# Polarfire SoC register map
Vendor: Microchip; File version: 1.0
CPU: Microchip PolarFire SoC 1.0, little endian
Registers are 32-bit, read-write, reset 0x0 unless marked. A register's access mark holds for its fields unless they carry their own. Offsets are from the block's base; [hi:lo] are bit positions.

## GEM_A_LO (part 6 of 8) — GEM_A_LO Controller
Base 0x20110000
Same registers: GEM_B_LO 0x20112000, GEM_A_HI 0x28110000, GEM_B_HI 0x28112000
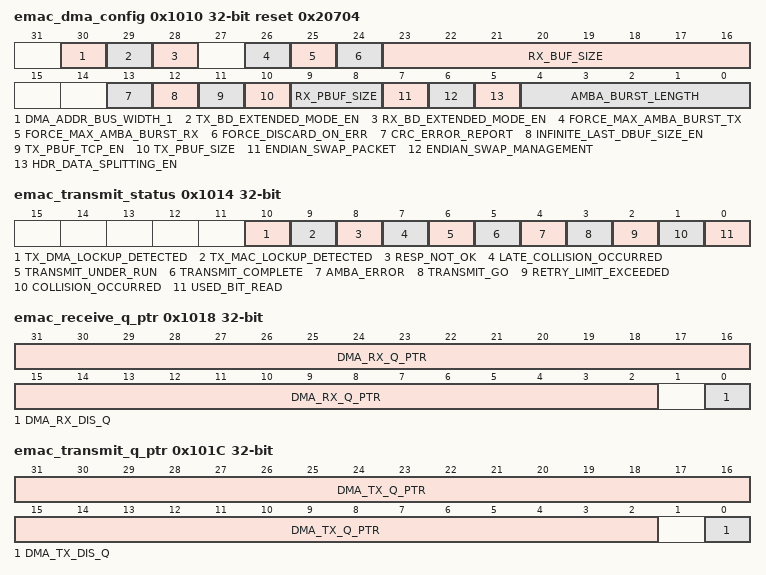
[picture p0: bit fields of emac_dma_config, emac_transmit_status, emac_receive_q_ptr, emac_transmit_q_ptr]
0x1010 emac_dma_config reset 0x20704 — DMA Configuration Register
  [30] DMA_ADDR_BUS_WIDTH_1 — DMA address bus width. 0 = 32b, 1 = 64b.
  [29] TX_BD_EXTENDED_MODE_EN — Enable TX extended BD mode. See TX BD control register definition for description of feature.
  [28] RX_BD_EXTENDED_MODE_EN — Enable RX extended BD mode. See RX BD control register definition for description of feature.
  [26] FORCE_MAX_AMBA_BURST_TX — Force max length bursts on TX. Force the TX DMA to always issue max length bursts on EOP (end of packet) or EOB (end of buffer) transfers as defined by bits 4:0 of this register, even when there is less than max burst data bytes to read. Residual data read is ignored. AHB only - does not apply on AXI bursts (prior to release 1p10) or bursts that break 1k boundary rule - supported on AXI from release 1p10.
  [25] FORCE_MAX_AMBA_BURST_RX — Force max length bursts on RX. Force the RX DMA to always issue max length bursts on EOP (end of packet) or EOB (end of buffer) transfers, even if there is less than max burst real packet data required to write. Any extra bytes of pad data is set to 0x00. AHB only - does not apply on AXI bursts (prior to release 1p10) or bursts that break 1k boundary rule - supported on AXI from release 1p10.
  [24] FORCE_DISCARD_ON_ERR — Auto Discard RX frames during lack of resource. When set, the GEM DMA will automatically discard the next frame (that is the oldest frame) from the receiver packet buffer memory when a receive buffer descriptor is read with its used bit set. When low, then received frames will remain to be stored in the SRAM based packet buffer until AMBA (AHB/AXI) buffer resource next becomes available. In this case if the SRAM memory fills up then there will be a receive overflow condition and the most recently received frame (that is the newest) will be discarded. A write to this bit is ignored if the DMA is not configured in the packet buffer full store and forward mode.
  [23:16] RX_BUF_SIZE — DMA receive buffer size in external AMBA (AHB/AXI) system memory. The value defined by these bits determines the size of buffer to use in main system memory when writing received data. The value is defined in multiples of 64 bytes., :0x01 corresponds to buffers of 64 bytes, :0x02 corresponds to 128 bytes etc., :For example:, :0x02: 128 byte., :0x18: 1536 byte (1*max length frame/buffer), :0xA0: 10240 byte (1*10K jumbo frame/buffer), :0xFF: 16320 byte , :Note that this value should never be written as zero., :Note. The reset value of this field is equal to the gem_rx_buffer_length_def define, which is user configurable.
  [13] CRC_ERROR_REPORT — When the bit is set, bit 16 of the receive buffer descriptor will represent FCS/CRC error (only if frames with FCS are copied to memory as enabled by bit 26 in the network config register). When this bit is clear, bit 16 of the receive buffer descriptor will represent the Canonical format indicator (CFI) bit as extracted from the receive frame (if the receive buffer descriptor is pointing to the last data buffer of the receive frame and the received frame was VLAN tagged).
  [12] INFINITE_LAST_DBUF_SIZE_EN — Forces the receive DMA to consider the data buffer pointed to by last descriptor in the descriptor list to be of elastic size (the last descriptor is the one with its wrap bit set). This means the first buffer pointed to in the list will always contain the beginning of a frame (this helps if there is a desire to build custom logic that interfaces with the receive buffer directly without software intervention). When set the rx_buf_size bits 23:16 in the dma configuration register are ignored for the last receive buffer in the descriptor list and data will be written into the buffer sequentially until the frame is completely received and the buffer descriptor status will be updated with the frame length as normal.
  [11] TX_PBUF_TCP_EN — Transmitter IP, TCP and UDP checksum generation offload enable (not supported when in TX Partial Store and Forward mode). When set, the transmitter checksum generation engine is enabled, to calculate and substitute checksums for transmit frames. When clear, frame data is unaffected. If the GEM is not configured to use the DMA packet buffer, this bit is not implemented and will be treated as reserved, read as 0, ignored on write.
  [10] TX_PBUF_SIZE — Transmitter packet buffer memory size select. Having this bit at zero halves the amount of memory used for the transmit packet buffer. This reduces the amount of memory used by the GEM. It is important to set this bit to one if the full configured physical memory is available. The value in brackets below represents the size that would result for the default maximum configured memory size of 4 Kbytes., :1: Use full configured addressable space (4 Kb), :0: Do not use top address bit (2 Kb), :If the GEM is not configured to use the DMA packet buffer, this bit is not implemented and will be treated as reserved, read as 0, ignored on write., :Note. The reset value of this field is equal to the gem_tx_pbuf_size_def define, which is user configurable.
  [9:8] RX_PBUF_SIZE — Receiver packet buffer memory size select. Having these bits at less than 11 reduces the amount of memory used for the receive packet buffer. This reduces the amount of memory used by the GEM. It is important to set these bits both to one if the full configured physical memory is available. The value in brackets below represents the size that would result for the default maximum configured memory size of 8 Kbytes., :11: Use full configured addressable space (8 Kb), :10: Do not use top address bit (4 Kb), :01: Do not use top two address bits (2 Kb), :00: Do not use top three address bits (1 Kb), :If the GEM is not configured to use the DMA packet buffer, these bits are not implemented and will be treated as reserved, read as 0, ignored on write., :Note. The reset value of this field is equal to the gem_rx_pbuf_size_def define, which is user configurable.
  [7] ENDIAN_SWAP_PACKET — endian swap mode enable for packet data accesses. When set, selects swapped endianism for AMBA (AHB/AXI) transfers. When clear, selects little endian mode.
  [6] ENDIAN_SWAP_MANAGEMENT — endian swap mode enable for management descriptor accesses. When set, selects swapped endianism for AMBA (AHB/AXI) transfers. When clear, selects little endian mode.
  [5] HDR_DATA_SPLITTING_EN — Enable header data Splitting. When set, receive frames will be forwarded to main memory using a minimum of two DMA data buffers. The first X data buffers will contain the frame header, consisting of the Ethernet,VLAN,(IPv4 or IPv6),(TCP or UDP). X= (frame header size divided by rx_buf_size as defined in bits 23:16 of this register). The last Y data buffers will contain the frame payload. Y= (frame payload size divided by rx_buf_size). Note that for non VLAN/IP/TCP/UDP frames, the header will always be 14 bytes. When this feature is disabled, the frame is forwarded to main memory in blocks of rx_buf_size.
  [4:0] AMBA_BURST_LENGTH — Selects the burst length to use on the AMBA (AHB/AXI) when transferring frame data. Not used for DMA management operations and only used where space and data size allow and respecting AXI/AHB burst boundary rules. One-hot priority encoding enforced automatically on register writes as follows, where x represents don't care:, :1xxxx: Attempt to use bursts of up to 16., :01xxx: Attempt to use bursts of up to 8., :001xx: Attempt to use bursts of up to 4., :0001x: Always use SINGLE bursts., :00001: Always use SINGLE bursts., :00000: Attempt to use bursts of up to 256.
0x1014 emac_transmit_status — This register, when read, provides details of the status of the transmit path. Once read, individual bits may be cleared by writing 1 to them. It is not possible to set a bit to 1 by writing to the register.
  [10] TX_DMA_LOCKUP_DETECTED — TX DMA lockup detected - set when lockup has been detected the transmit DMA lockup monitor.
  [9] TX_MAC_LOCKUP_DETECTED — TX MAC lockup detected - set when lockup has been detected by the lockup monitor on the MAC transmit path.
  [8] RESP_NOT_OK — bresp/hresp not OK - set when the DMA block sees bresp/hresp not OK. Cleared by writing a one to this bit.
  [7] LATE_COLLISION_OCCURRED — Late collision occurred - only set if the condition occurs in gigabit mode, as retry is not attempted. Cleared by writing a one to this bit.
  [6] TRANSMIT_UNDER_RUN — Transmit under run - this bit is set if the transmitter was forced to terminate a frame that it had already began transmitting due to further data being unavailable. This bit is set if a transmitter status write back has not completed when another status write back is attempted. When using the DMA interface configured for internal FIFO mode, this bit is also set when the transmit DMA has written the SOP data into the FIFO and either the AHB bus was not granted in time for further data, or because an AHB not OK response was returned, or because a used bit was read. When using the DMA interface configured for packet buffer mode, this bit will never be set. When using the external FIFO interface, this bit is also set when the tx_r_underflow input is asserted during a frame transfer. Cleared by writing a 1.
  [5] TRANSMIT_COMPLETE — Transmit complete - set when a frame has been transmitted. Cleared by writing a one to this bit.
  [4] AMBA_ERROR — Transmit frame corruption due to AMBA (AHB/AXI) errors. Set if an error occurs whilst midway through reading transmit frame from external memory including HRESP(AHB), RRESP or BRESP(AXI) errors and buffers exhausted mid frame (if the buffers run out during transmission of a frame then transmission stops, FCS shall be bad and tx_er asserted). Also set in DMA packet buffer mode if single frame is too large for configured packet buffer memory size. Cleared by writing a one to this bit.
  [3] TRANSMIT_GO ro — Transmit go - if high transmit is active. When using the exposed FIFO interface, this bit represents bit 3 of the network control register. When using the DMA interface this bit represents the tx_go variable as specified in the transmit buffer description.
  [2] RETRY_LIMIT_EXCEEDED — Retry limit exceeded - cleared by writing a one to this bit.
  [1] COLLISION_OCCURRED — Collision occurred - set by the assertion of collision. Cleared by writing a one to this bit. When operating in 10/100 mode, this status indicates either a collision or a late collision. In gigabit mode, this status is not set for a late collision.
  [0] USED_BIT_READ — Used bit read - set when a transmit buffer descriptor is read with its used bit set. Cleared by writing a one to this bit.
0x1018 emac_receive_q_ptr — This register holds the start address of the receive buffer queue (receive buffers descriptor list). The receive buffer queue base address must be initialized before receive is enabled through bit 2 of the network control register. Once reception is enabled, any write to the receive buffer queue base address register is ignored. Reading this register returns the location of the descriptor currently being accessed. This value increments as buffers are used. Software should not use this register for determining where to remove received frames from the queue as it constantly changes as new frames are received. Software should instead work its way through the buffer descriptor queue checking the used bits. In terms of AMBA (AHB/AXI) operation, the receive descriptors are read from memory using a single 32bit AHB/AXI access. When the datapath is configured at 64bit or 128bit, the receive descriptors should be aligned at 64-bit boundaries and each pair of 32-bit descriptors is written to using a single 64bit AHB/AXI access. For 32bit datapaths, the receive descriptors should be aligned at 32-bit boundaries and are written to using two individual non sequential 32-bit accesses.
  [31:2] DMA_RX_Q_PTR — Receive buffer queue base address - written with the address of the start of the receive queue.
  [0] DMA_RX_DIS_Q — Disable queue if set to 1. This can be used to reduce the number of active queues and should only be changed while receive is not enabled.
0x101C emac_transmit_q_ptr — This register holds the start address of the transmit buffer queue (transmit buffers descriptor list). The transmit buffer queue base address register must be initialized before transmit is started through bit 9 of the network control register. Once transmission has started, any write to the transmit buffer queue base address register is illegal and therefore ignored. Note that due to clock boundary synchronization, it takes a maximum of four pclk cycles from the writing of the transmit start bit before the transmitter is active. Writing to the transmit buffer queue base address register during this time may produce unpredictable results. Reading this register returns the location of the descriptor currently being accessed. Because the DMA can store data for multiple frames at once, this may not necessarily be pointing to the current frame being transmitted. In terms of AMBA AHB/AXI operation, the transmit descriptors are written to memory using a single 32bit AHB access. When the datapath is configured as 64bit or 128bit, the transmit descriptors should be aligned at 64-bit boundaries and each pair of 32-bit descriptors is read from memory using a single AHB/AXI access. For 32bit datapaths, the descriptors should be aligned at 32-bit boundaries and the descriptors are read from memory using two individual 32-bit non sequential accesses.
  [31:2] DMA_TX_Q_PTR — Transmit buffer queue base address - written with the address of the start of the transmit queue.
  [0] DMA_TX_DIS_Q — Disable queue if set to 1. This can be used to reduce the number of active queues and should only be changed while transmit is not enabled.
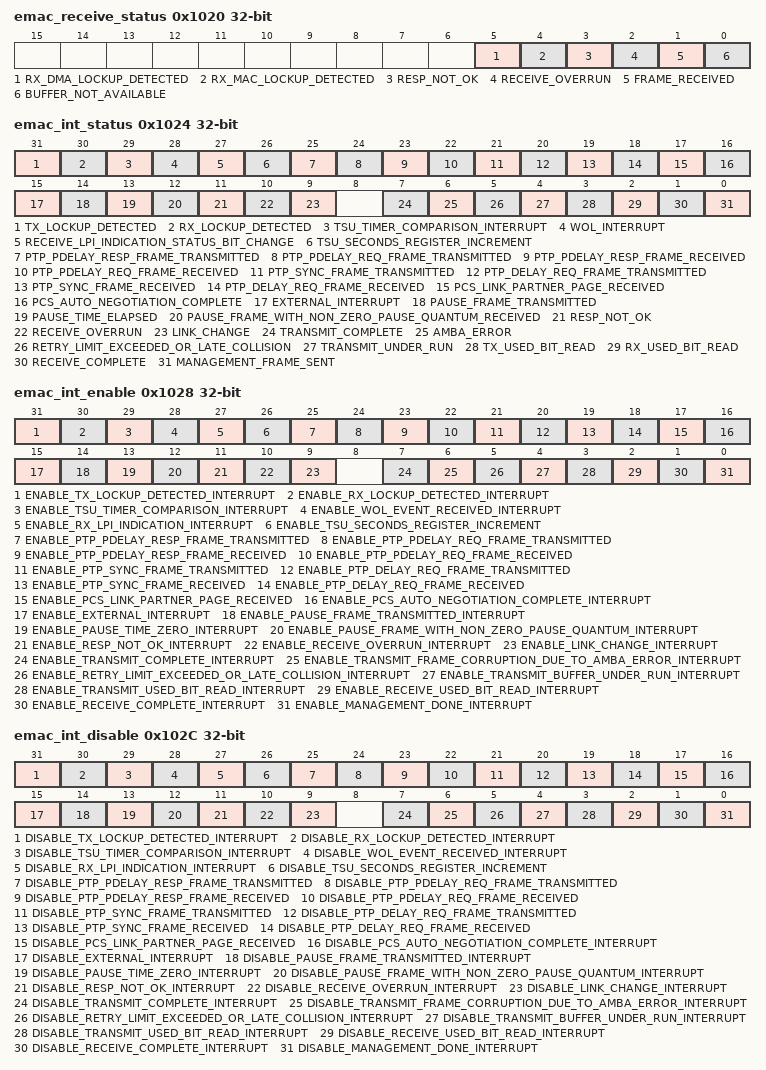
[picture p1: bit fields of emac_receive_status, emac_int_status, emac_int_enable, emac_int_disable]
0x1020 emac_receive_status — This register, when read provides details of the status of the receive path. Once read, individual bits may be cleared by writing 1 to them. It is not possible to set a bit to 1 by writing to the register.
  [5] RX_DMA_LOCKUP_DETECTED — RX DMA lockup detected - set when lockup has been detected the receive DMA lockup monitor.
  [4] RX_MAC_LOCKUP_DETECTED — RX MAC lockup detected - set when lockup has been detected by the lockup monitor on the MAC receive path.
  [3] RESP_NOT_OK — bresp/hresp not OK - set when the DMA block sees bresp/hresp not OK. Cleared by writing a one to this bit.
  [2] RECEIVE_OVERRUN — Receive overrun - this bit is set if either the gem_dma RX FIFO or external RX FIFO were unable to store the receive frame due to a FIFO overflow, or if the receive status, reported by the gem_rx module to the gem_dma was not taken at end of frame. This bit is also set in DMA packet buffer mode if the packet buffer overflows. For DMA operation the buffer will be recovered if an overrun occurs. This bit is cleared by writing a one to it.
  [1] FRAME_RECEIVED — Frame received - one or more frames have been received and placed in memory. Cleared by writing a one to this bit.
  [0] BUFFER_NOT_AVAILABLE — Buffer not available - an attempt was made to get a new buffer and the pointer indicated that it was owned by the processor. The DMA will reread the pointer each time an end of frame is received until a valid pointer is found. This bit is set following each descriptor read attempt that fails, even if consecutive pointers are unsuccessful and software has in the meantime cleared the status flag. Cleared by writing a one to this bit.
0x1024 emac_int_status — If not configured for priority queuing, the GEM generates a single interrupt. This register indicates the source of this interrupt. The corresponding bit in the mask register must be clear for a bit to be set. If any bit is set in this register the ethernet_int signal will be asserted. For test purposes each bit can be set or reset by writing to the interrupt mask register. The default configuration is shown below whereby all bits are reset to zero on read. Changing the validity of the 'gem_irq_read_clear define will instead require a one to be written to the appropriate bit in order to clear it. In this mode reading has no effect on the status of the bit.
  [31] TX_LOCKUP_DETECTED — TX lockup detection - set when lockup has been detected by any of the lockup monitors on the transmit datapath.
  [30] RX_LOCKUP_DETECTED — RX lockup detection - set when lockup has been detected by any of the lockup monitors on the receive datapath.
  [29] TSU_TIMER_COMPARISON_INTERRUPT — TSU timer comparison interrupt. Indicates when TSU timer count value is equal to programmed value.
  [28] WOL_INTERRUPT — WOL interrupt. Indicates a WOL event has been received.
  [27] RECEIVE_LPI_INDICATION_STATUS_BIT_CHANGE
  [26] TSU_SECONDS_REGISTER_INCREMENT — TSU seconds register increment indicates the register has incremented. Cleared on read.
  [25] PTP_PDELAY_RESP_FRAME_TRANSMITTED — PTP pdelay_resp frame transmitted indicates a PTP pdelay_resp frame has been transmitted. Cleared on read.
  [24] PTP_PDELAY_REQ_FRAME_TRANSMITTED — PTP pdelay_req frame transmitted indicates a PTP pdelay_req frame has been transmitted. Cleared on read.
  [23] PTP_PDELAY_RESP_FRAME_RECEIVED — PTP pdelay_resp frame received indicates a PTP pdelay_resp frame has been received. Cleared on read.
  [22] PTP_PDELAY_REQ_FRAME_RECEIVED — PTP pdelay_req frame received indicates a PTP pdelay_req frame has been received. Cleared on read.
  [21] PTP_SYNC_FRAME_TRANSMITTED — PTP sync frame transmitted indicates a PTP sync frame has been transmitted. Cleared on read.
  [20] PTP_DELAY_REQ_FRAME_TRANSMITTED — PTP delay_req frame transmitted indicates a PTP delay_req frame has been transmitted. Cleared on read.
  [19] PTP_SYNC_FRAME_RECEIVED — PTP sync frame received indicates a PTP sync frame has been received. Cleared on read.
  [18] PTP_DELAY_REQ_FRAME_RECEIVED — PTP delay_req frame received indicates a PTP delay_req frame has been received. Cleared on read.
  [17] PCS_LINK_PARTNER_PAGE_RECEIVED — PCS link partner page received - set when a new base page or next page is received from the link partner. The first time this interrupt is received, it will indicate base page received and subsequent reads will indicate next pages. The next page and base page registers should only be read when this interrupt is signalled. For next pages, the link partner next page register should be read first to avoid the register being over written. This interrupt also indicates when the host should write a new page into the next page register. If further next page exchange is only required by the link partner, this register should be written with a null message page (0x2001). Cleared on read.
  [16] PCS_AUTO_NEGOTIATION_COMPLETE — PCS auto-negotiation complete - set once the internal PCS layer has completed auto-negotiation. Cleared on read.
  [15] EXTERNAL_INTERRUPT — External interrupt - set when a rising edge has been detected on the ext_interrupt_in input pin. Cleared on read.
  [14] PAUSE_FRAME_TRANSMITTED — Pause frame transmitted - indicates a pause frame has been successfully transmitted after being initiated from the network control register or from the tx_pause control pin. Cleared on read.
  [13] PAUSE_TIME_ELAPSED — Pause Time elapsed - set when either the pause time register at address 0x38 decrements to zero, or when a valid pause frame is received with a zero pause quantum field. Not set for PFC pause frames. Cleared on read.
  [12] PAUSE_FRAME_WITH_NON_ZERO_PAUSE_QUANTUM_RECEIVED — Pause frame with non-zero pause quantum received - indicates a valid legacy pause frame with a non-zero pause quantum field has been received or any valid PFC pause frame has been received. Cleared on read.
  [11] RESP_NOT_OK — bresp/hresp not OK - set when the DMA block sees bresp/hresp not OK. Cleared on read.
  [10] RECEIVE_OVERRUN — Receive overrun - set when the receive overrun status bit gets set. Cleared on read.
  [9] LINK_CHANGE — Link change - set when the PCS link status changes. If auto-negotiation is enabled then link status goes high when it completes. If AN is disabled link status goes high when synchronization is achieved. If 802.3cb link fault signalling is enabled a link change interrupt is triggered when the link fault indication as reported in the network status register changes. Cleared on read.
  [7] TRANSMIT_COMPLETE — Transmit complete - set when a frame has been transmitted. Cleared on read.
  [6] AMBA_ERROR — Transmit frame corruption due to AMBA (AHB/AXI) error. Set if an error occurs whilst midway through reading transmit frame from external system memory, including HRESP errors(AHB), RRESP or BRESP(AXI) errors and buffers exhausted mid frame (if the buffers run out during transmission of a frame then transmission stops, FCS shall be bad and tx_er asserted). Also set in DMA packet buffer mode if single frame is too large for configured packet buffer memory size. Cleared on a read.
  [5] RETRY_LIMIT_EXCEEDED_OR_LATE_COLLISION — Retry limit exceeded or late collision - transmit error. Late collision will only cause this status bit to be set in gigabit mode (as a retry is not attempted). Cleared on read.
  [4] TRANSMIT_UNDER_RUN — Transmit under run - this interrupt is set if the transmitter was forced to terminate a frame that it has already began transmitting due to further data being unavailable. If an under run occurs, the transmitter will force bad crc and tx_er high. This interrupt is set if a transmitter status write back has not completed when another status write back is attempted. When using the DMA interface configured for internal FIFO mode, this interrupt is also set when the transmit DMA has written the SOP data into the FIFO and either the AHB bus was not granted in time for further data, or because an AHB/AXI error response was returned by the connected slave, or because a used bit was read. When using the DMA interface configured for packet buffer mode, this bit will never be set. When using the external FIFO interface, this interrupt is also set when the tx_r_underflow input was asserted during a frame transfer. Cleared on read.
  [3] TX_USED_BIT_READ — TX used bit read - set when a transmit buffer descriptor is read with its used bit set. Cleared on read.
  [2] RX_USED_BIT_READ — RX used bit read - set when a receive buffer descriptor is read with its used bit set. Cleared on read.
  [1] RECEIVE_COMPLETE — Receive complete - a frame has been stored in memory. Cleared on read.
  [0] MANAGEMENT_FRAME_SENT — Management frame sent - the PHY management register has completed its operation. Cleared on read.
0x1028 emac_int_enable — At reset all interrupts are disabled. Writing a one to the relevant bit location enables the required interrupt. This register is write only and when read will return zero.
  [31] ENABLE_TX_LOCKUP_DETECTED_INTERRUPT — Enable TX lockup detection interrupt.
  [30] ENABLE_RX_LOCKUP_DETECTED_INTERRUPT — Enable RX lockup detection interrupt.
  [29] ENABLE_TSU_TIMER_COMPARISON_INTERRUPT
  [28] ENABLE_WOL_EVENT_RECEIVED_INTERRUPT
  [27] ENABLE_RX_LPI_INDICATION_INTERRUPT
  [26] ENABLE_TSU_SECONDS_REGISTER_INCREMENT
  [25] ENABLE_PTP_PDELAY_RESP_FRAME_TRANSMITTED
  [24] ENABLE_PTP_PDELAY_REQ_FRAME_TRANSMITTED
  [23] ENABLE_PTP_PDELAY_RESP_FRAME_RECEIVED
  [22] ENABLE_PTP_PDELAY_REQ_FRAME_RECEIVED
  [21] ENABLE_PTP_SYNC_FRAME_TRANSMITTED
  [20] ENABLE_PTP_DELAY_REQ_FRAME_TRANSMITTED
  [19] ENABLE_PTP_SYNC_FRAME_RECEIVED
  [18] ENABLE_PTP_DELAY_REQ_FRAME_RECEIVED
  [17] ENABLE_PCS_LINK_PARTNER_PAGE_RECEIVED
  [16] ENABLE_PCS_AUTO_NEGOTIATION_COMPLETE_INTERRUPT
  [15] ENABLE_EXTERNAL_INTERRUPT
  [14] ENABLE_PAUSE_FRAME_TRANSMITTED_INTERRUPT
  [13] ENABLE_PAUSE_TIME_ZERO_INTERRUPT
  [12] ENABLE_PAUSE_FRAME_WITH_NON_ZERO_PAUSE_QUANTUM_INTERRUPT
  [11] ENABLE_RESP_NOT_OK_INTERRUPT — Enable bresp/hresp not OK interrupt
  [10] ENABLE_RECEIVE_OVERRUN_INTERRUPT
  [9] ENABLE_LINK_CHANGE_INTERRUPT
  [7] ENABLE_TRANSMIT_COMPLETE_INTERRUPT
  [6] ENABLE_TRANSMIT_FRAME_CORRUPTION_DUE_TO_AMBA_ERROR_INTERRUPT — Enable transmit frame corruption due to AMBA (AHB/AXI) error interrupt
  [5] ENABLE_RETRY_LIMIT_EXCEEDED_OR_LATE_COLLISION_INTERRUPT
  [4] ENABLE_TRANSMIT_BUFFER_UNDER_RUN_INTERRUPT
  [3] ENABLE_TRANSMIT_USED_BIT_READ_INTERRUPT
  [2] ENABLE_RECEIVE_USED_BIT_READ_INTERRUPT
  [1] ENABLE_RECEIVE_COMPLETE_INTERRUPT
  [0] ENABLE_MANAGEMENT_DONE_INTERRUPT
0x102C emac_int_disable — Writing a 1 to the relevant bit location disables that particular interrupt. This register is write only and when read will return zero.
  [31] DISABLE_TX_LOCKUP_DETECTED_INTERRUPT — Disable TX lockup detection interrupt.
  [30] DISABLE_RX_LOCKUP_DETECTED_INTERRUPT — Disable RX lockup detection interrupt.
  [29] DISABLE_TSU_TIMER_COMPARISON_INTERRUPT
  [28] DISABLE_WOL_EVENT_RECEIVED_INTERRUPT
  [27] DISABLE_RX_LPI_INDICATION_INTERRUPT
  [26] DISABLE_TSU_SECONDS_REGISTER_INCREMENT
  [25] DISABLE_PTP_PDELAY_RESP_FRAME_TRANSMITTED
  [24] DISABLE_PTP_PDELAY_REQ_FRAME_TRANSMITTED
  [23] DISABLE_PTP_PDELAY_RESP_FRAME_RECEIVED
  [22] DISABLE_PTP_PDELAY_REQ_FRAME_RECEIVED
  [21] DISABLE_PTP_SYNC_FRAME_TRANSMITTED
  [20] DISABLE_PTP_DELAY_REQ_FRAME_TRANSMITTED
  [19] DISABLE_PTP_SYNC_FRAME_RECEIVED
  [18] DISABLE_PTP_DELAY_REQ_FRAME_RECEIVED
  [17] DISABLE_PCS_LINK_PARTNER_PAGE_RECEIVED
  [16] DISABLE_PCS_AUTO_NEGOTIATION_COMPLETE_INTERRUPT
  [15] DISABLE_EXTERNAL_INTERRUPT
  [14] DISABLE_PAUSE_FRAME_TRANSMITTED_INTERRUPT
  [13] DISABLE_PAUSE_TIME_ZERO_INTERRUPT
  [12] DISABLE_PAUSE_FRAME_WITH_NON_ZERO_PAUSE_QUANTUM_INTERRUPT
  [11] DISABLE_RESP_NOT_OK_INTERRUPT — Disable bresp/hresp not OK interrupt
  [10] DISABLE_RECEIVE_OVERRUN_INTERRUPT
  [9] DISABLE_LINK_CHANGE_INTERRUPT
  [7] DISABLE_TRANSMIT_COMPLETE_INTERRUPT
  [6] DISABLE_TRANSMIT_FRAME_CORRUPTION_DUE_TO_AMBA_ERROR_INTERRUPT — Disable transmit frame corruption due to AMBA (AHB/AXI) error interrupt
  [5] DISABLE_RETRY_LIMIT_EXCEEDED_OR_LATE_COLLISION_INTERRUPT
  [4] DISABLE_TRANSMIT_BUFFER_UNDER_RUN_INTERRUPT
  [3] DISABLE_TRANSMIT_USED_BIT_READ_INTERRUPT
  [2] DISABLE_RECEIVE_USED_BIT_READ_INTERRUPT
  [1] DISABLE_RECEIVE_COMPLETE_INTERRUPT
  [0] DISABLE_MANAGEMENT_DONE_INTERRUPT
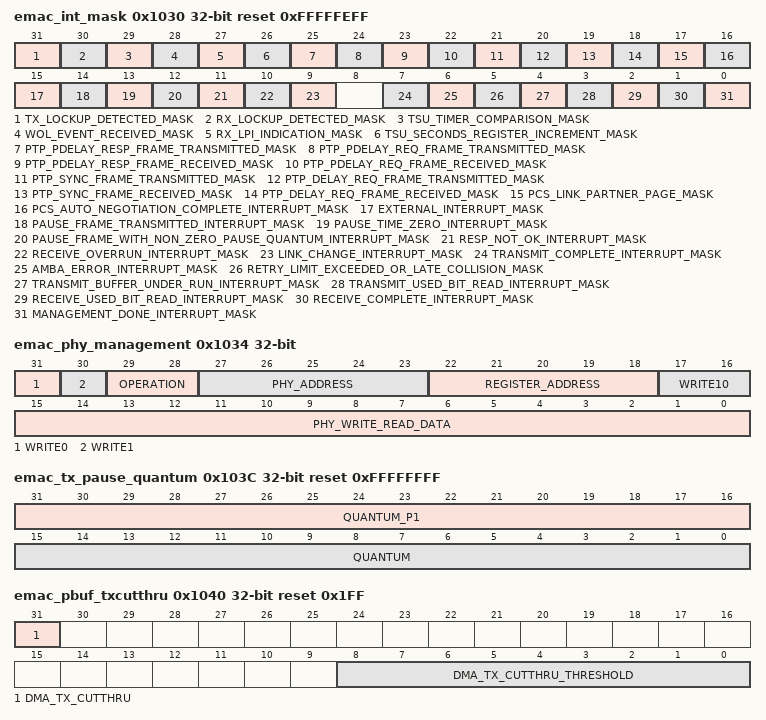
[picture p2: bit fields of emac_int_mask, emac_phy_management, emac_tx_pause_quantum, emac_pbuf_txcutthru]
0x1030 emac_int_mask ro reset 0xFFFFFEFF — The interrupt mask register is a read only register indicating which interrupts are masked. All bits are set at reset and can be reset individually by writing to the interrupt enable register or set individually by writing to the interrupt disable register. Having separate address locations for enable and disable saves the need for performing a read modify write when updating the interrupt mask register. For test purposes there is a write-only function to this register that allows the bits in the interrupt status register to be set or cleared, regardless of the state of the mask register.
  [31] TX_LOCKUP_DETECTED_MASK — TX lockup interrupt mask.
  [30] RX_LOCKUP_DETECTED_MASK — RX lockup interrupt mask.
  [29] TSU_TIMER_COMPARISON_MASK — Enable TSU timer comparison interrupt mask.
  [28] WOL_EVENT_RECEIVED_MASK — A read of this register returns the value of the WOL event received mask., :0: Interrupt is enabled., :1: Interrupt is disabled., :A write to this register directly affects the state of the corresponding bit in the interrupt status register, causing an interrupt to be generated if a 1 is written.
  [27] RX_LPI_INDICATION_MASK — A read of this register returns the value of the RX LPI indication mask., :0: Interrupt is enabled., :1: Interrupt is disabled., :A write to this register directly affects the state of the corresponding bit in the interrupt status register, causing an interrupt to be generated if a 1 is written
  [26] TSU_SECONDS_REGISTER_INCREMENT_MASK — A read of this register returns the value of the TSU seconds register increment mask., :0: Interrupt is enabled., :1: Interrupt is disabled., :A write to this register directly affects the state of the corresponding bit in the interrupt status register, causing an interrupt to be generated if a 1 is written.
  [25] PTP_PDELAY_RESP_FRAME_TRANSMITTED_MASK — A read of this register returns the value of the PTP pdelay_resp frame transmitted mask., :0: Interrupt is enabled., :1: Interrupt is disabled., :A write to this register directly affects the state of the corresponding bit in the interrupt status register, causing an interrupt to be generated if a 1 is written.
  [24] PTP_PDELAY_REQ_FRAME_TRANSMITTED_MASK — A read of this register returns the value of the PTP pdelay_req frame transmitted mask., :0: Interrupt is enabled., :1: Interrupt is disabled., :A write to this register directly affects the state of the corresponding bit in the interrupt status register, causing an interrupt to be generated if a 1 is written.
  [23] PTP_PDELAY_RESP_FRAME_RECEIVED_MASK — A read of this register returns the value of the PTP pdelay_resp frame received mask., :0: Interrupt is enabled., :1: Interrupt is disabled., :A write to this register directly affects the state of the corresponding bit in the interrupt status register, causing an interrupt to be generated if a 1 is written.
  [22] PTP_PDELAY_REQ_FRAME_RECEIVED_MASK — A read of this register returns the value of the PTP pdelay_req frame received mask., :0: Interrupt is enabled., :1: Interrupt is disabled., :A write to this register directly affects the state of the corresponding bit in the interrupt status register, causing an interrupt to be generated if a 1 is written.
  [21] PTP_SYNC_FRAME_TRANSMITTED_MASK — A read of this register returns the value of the PTP sync frame transmitted mask., :0: Interrupt is enabled., :1: Interrupt is disabled., :A write to this register directly affects the state of the corresponding bit in the interrupt status register, causing an interrupt to be generated if a 1 is written.
  [20] PTP_DELAY_REQ_FRAME_TRANSMITTED_MASK — A read of this register returns the value of the PTP delay_req frame transmitted mask., :0: Interrupt is enabled., :1: Interrupt is disabled., :A write to this register directly affects the state of the corresponding bit in the interrupt status register, causing an interrupt to be generated if a 1 is written.
  [19] PTP_SYNC_FRAME_RECEIVED_MASK — A read of this register returns the value of the PTP sync frame received mask., :0: Interrupt is enabled., :1: Interrupt is disabled., :A write to this register directly affects the state of the corresponding bit in the interrupt status register, causing an interrupt to be generated if a 1 is written.
  [18] PTP_DELAY_REQ_FRAME_RECEIVED_MASK — A read of this register returns the value of the PTP delay_req frame received mask., :0: Interrupt is enabled., :1: Interrupt is disabled., :A write to this register directly affects the state of the corresponding bit in the interrupt status register, causing an interrupt to be generated if a 1 is written.
  [17] PCS_LINK_PARTNER_PAGE_MASK — A read of this register returns the value of the PCS link partner page mask., :0: Interrupt is enabled., :1: Interrupt is disabled., :A write to this register directly affects the state of the corresponding bit in the interrupt status register, causing an interrupt to be generated if a 1 is written.
  [16] PCS_AUTO_NEGOTIATION_COMPLETE_INTERRUPT_MASK — A read of this register returns the value of the PCS auto-negotiation complete interrupt mask., :0: Interrupt is enabled., :1: Interrupt is disabled., :A write to this register directly affects the state of the corresponding bit in the interrupt status register, causing an interrupt to be generated if a 1 is written.
  [15] EXTERNAL_INTERRUPT_MASK — External interrupt mask., :0: Interrupt is enabled., :1: Interrupt is disabled., :A write to this register directly affects the state of the corresponding bit in the interrupt status register, causing an interrupt to be generated if a 1 is written.
  [14] PAUSE_FRAME_TRANSMITTED_INTERRUPT_MASK — Pause frame transmitted interrupt mask., :0: Interrupt is enabled., :1: Interrupt is disabled., :A write to this register directly affects the state of the corresponding bit in the interrupt status register, causing an interrupt to be generated if a 1 is written.
  [13] PAUSE_TIME_ZERO_INTERRUPT_MASK — Pause time zero interrupt mask., :0: Interrupt is enabled., :1: Interrupt is disabled., :A write to this register directly affects the state of the corresponding bit in the interrupt status register, causing an interrupt to be generated if a 1 is written.
  [12] PAUSE_FRAME_WITH_NON_ZERO_PAUSE_QUANTUM_INTERRUPT_MASK — Pause frame with non-zero pause quantum interrupt mask., :0: Interrupt is enabled., :1: Interrupt is disabled. A write to this register directly affects the state of the corresponding bit in the interrupt status register, causing an interrupt to be generated if a 1 is written.
  [11] RESP_NOT_OK_INTERRUPT_MASK — bresp/hresp not OK interrupt mask., :0: Interrupt is enabled., :1: Interrupt is disabled., :A write to this register directly affects the state of the corresponding bit in the interrupt status register, causing an interrupt to be generated if a 1 is written.
  [10] RECEIVE_OVERRUN_INTERRUPT_MASK — Receive overrun interrupt mask., :0: Interrupt is enabled., :1: Interrupt is disabled., :A write to this register directly affects the state of the corresponding bit in the interrupt status register, causing an interrupt to be generated if a 1 is written.
  [9] LINK_CHANGE_INTERRUPT_MASK — A read of this register returns the value of the link change interrupt mask., :0: Interrupt is enabled., :1: Interrupt is disabled., :A write to this register directly affects the state of the corresponding bit in the interrupt status register, causing an interrupt to be generated if a 1 is written.
  [7] TRANSMIT_COMPLETE_INTERRUPT_MASK — Transmit complete interrupt mask., :0: Interrupt is enabled., :1: Interrupt is disabled., :A write to this register directly affects the state of the corresponding bit in the interrupt status register, causing an interrupt to be generated if a 1 is written.
  [6] AMBA_ERROR_INTERRUPT_MASK — Transmit frame corruption due to AMBA (AHB/AXI) error interrupt mask., :0: Interrupt is enabled., :1: Interrupt is disabled., :A write to this register directly affects the state of the corresponding bit in the interrupt status register, causing an interrupt to be generated if a 1 is written.
  [5] RETRY_LIMIT_EXCEEDED_OR_LATE_COLLISION_MASK — A read of this register returns the value of the retry limit exceeded or late collision (gigabit mode only) interrupt mask., :0: Interrupt is enabled., :1: Interrupt is disabled., :A write to this register directly affects the state of the corresponding bit in the interrupt status register, causing an interrupt to be generated if a 1 is written.
  [4] TRANSMIT_BUFFER_UNDER_RUN_INTERRUPT_MASK — Transmit buffer under run interrupt mask., :0: Interrupt is enabled., :1: Interrupt is disabled., :A write to this register directly affects the state of the corresponding bit in the interrupt status register, causing an interrupt to be generated if a 1 is written.
  [3] TRANSMIT_USED_BIT_READ_INTERRUPT_MASK — Transmit used bit read interrupt mask., :0: Interrupt is enabled., :1: Interrupt is disabled., :A write to this register directly affects the state of the corresponding bit in the interrupt status register, causing an interrupt to be generated if a 1 is written.
  [2] RECEIVE_USED_BIT_READ_INTERRUPT_MASK — Receive used bit read interrupt mask., :0: Interrupt is enabled., :1: Interrupt is disabled., :A write to this register directly affects the state of the corresponding bit in the interrupt status register, causing an interrupt to be generated if a 1 is written.
  [1] RECEIVE_COMPLETE_INTERRUPT_MASK — Receive complete interrupt mask., :0: Interrupt is enabled., :1: Interrupt is disabled., :A write to this register directly affects the state of the corresponding bit in the interrupt status register, causing an interrupt to be generated if a 1 is written.
  [0] MANAGEMENT_DONE_INTERRUPT_MASK — Management done interrupt mask., :0: Interrupt is enabled., :1: Interrupt is disabled., :A write to this register directly affects the state of the corresponding bit in the interrupt status register, causing an interrupt to be generated if a 1 is written.
0x1034 emac_phy_management — Do not use this register. The eMAC MDIO port is unconnected.
  [31] WRITE0 — Must be written with 0.
  [30] WRITE1 — Must be written to 1 for a valid Clause 22 frame and to 0 for a valid Clause 45 frame.
  [29:28] OPERATION — Operation. For a Clause 45 frame: 00 is an addr, 01 is a write, 10 is a post read increment, 11 is a read frame. For a Clause 22 frame: 10 is a read, 01 is a write.
  [27:23] PHY_ADDRESS
  [22:18] REGISTER_ADDRESS — Register address - specifies the register in the PHY to access.
  [17:16] WRITE10 — Must be written with 10.
  [15:0] PHY_WRITE_READ_DATA — For a write operation this is written with the data to be written to the PHY. After a read operation this contains the data read from the PHY.
0x1038 emac_pause_time ro — Received Pause Quantum Register
  [15:0] QUANTUM — Received pause quantum - stores the current value of the received pause quantum register which is decremented every 512 bit times.
0x103C emac_tx_pause_quantum reset 0xFFFFFFFF — Transmit Pause Quantum Register
  [31:16] QUANTUM_P1 — Transmit pause quantum - written with the pause quantum value for pause frame transmission of priority 1.
  [15:0] QUANTUM — Transmit pause quantum - written with the pause quantum value for pause frame transmission.
0x1040 emac_pbuf_txcutthru reset 0x1FF — Transmit Partial Store and Forward Register. Partial store and forward is only applicable when using the DMA configured in SRAM based packet buffer mode. It is also not available when using multi buffer frames. This register contains the enable bit and watermark value for transmit cut-through operation.
  [31] DMA_TX_CUTTHRU — Enable TX partial store and forward operation
  [8:0] DMA_TX_CUTTHRU_THRESHOLD — Watermark value corresponding to number of SRAM locations. This value must be >= 0x14. The actual number of bytes for the watermark is obtained by multiplying the watermark value by the value of the gem_tx_pbuf_data define divided by 8. The reset value depends on the value of the configuration option 'gem_emac_tx_pbuf_addr, which is defined in the verilog defs configuration file.
